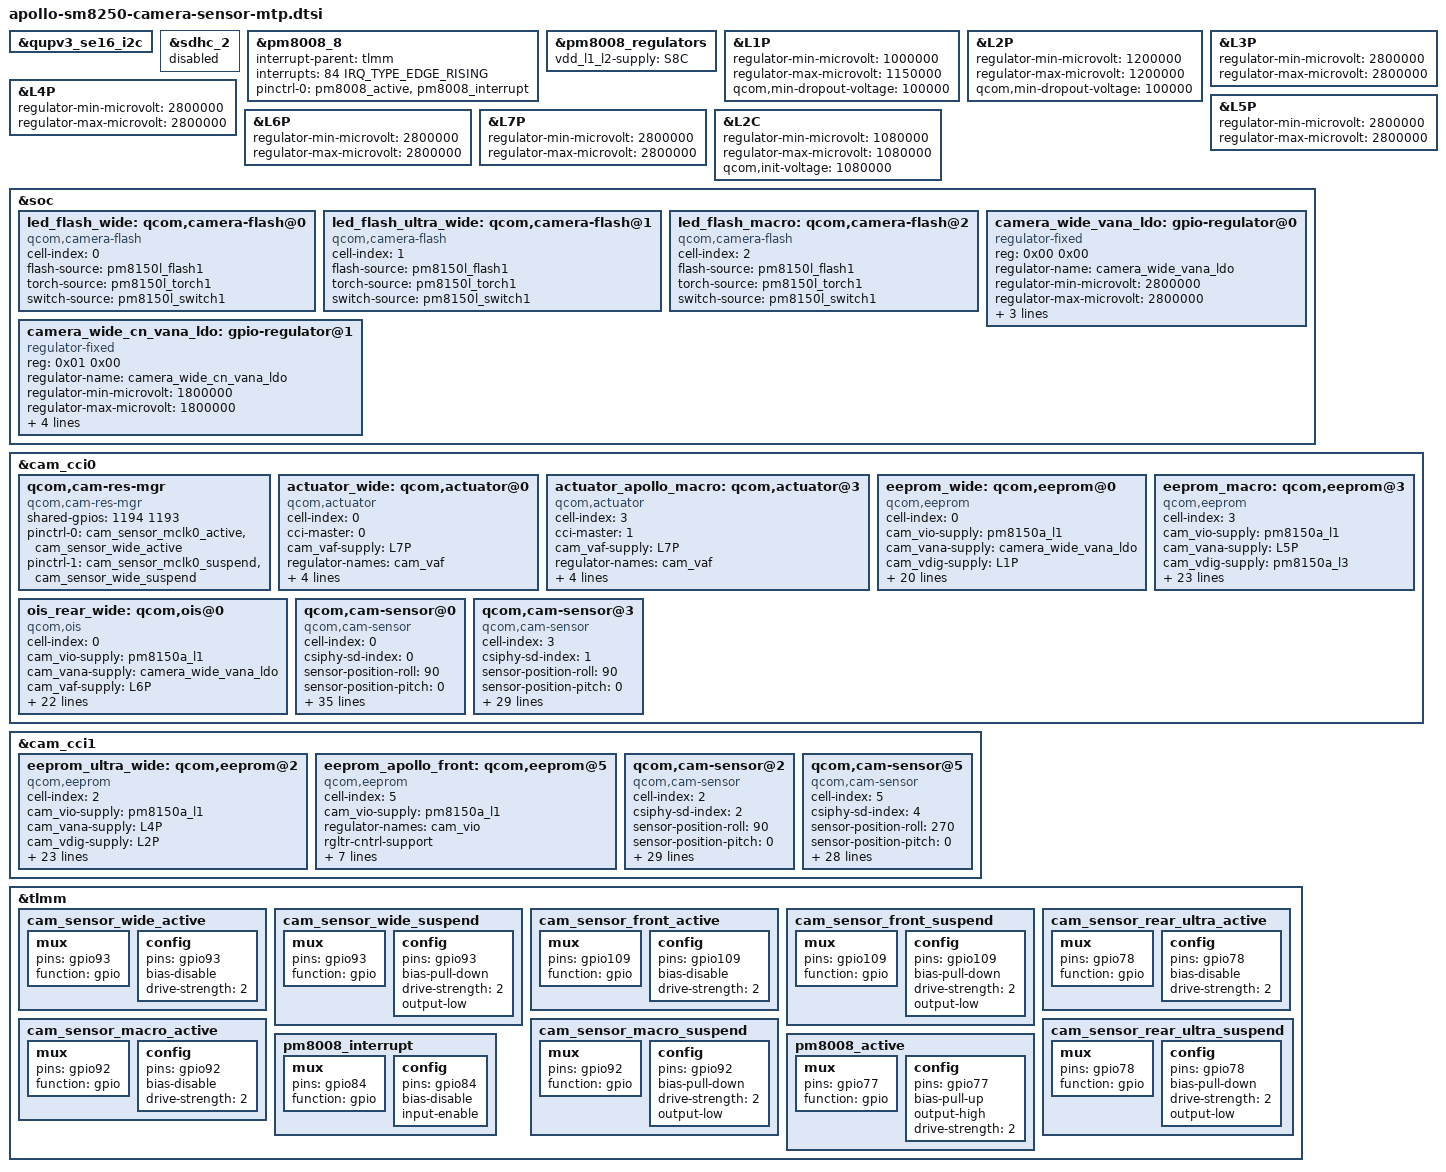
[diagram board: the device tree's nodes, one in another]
&qupv3_se16_i2c {
	status = "ok";
	#include "pm8008.dtsi"
};

&sdhc_2 {
	status = "disabled";
};
&pm8008_8 {
	/* PM8008 IRQ STAT */
	interrupt-parent = <&tlmm>;
	interrupts = <84 IRQ_TYPE_EDGE_RISING>;

	pinctrl-names = "default";
	pinctrl-0 = <&pm8008_active &pm8008_interrupt>;
};
&pm8008_regulators {
	vdd_l1_l2-supply = <&S8C>;
};
&L1P {
	regulator-min-microvolt = <1000000>;
	regulator-max-microvolt = <1150000>;
	qcom,min-dropout-voltage = <100000>;
};

&L2P {
	regulator-min-microvolt = <1200000>;
	regulator-max-microvolt = <1200000>;
	qcom,min-dropout-voltage = <100000>;
};

&L3P {
	regulator-min-microvolt = <2800000>;
	regulator-max-microvolt = <2800000>;
};

&L4P {
	regulator-min-microvolt = <2800000>;
	regulator-max-microvolt = <2800000>;
};

&L5P {
	regulator-min-microvolt = <2800000>;
	regulator-max-microvolt = <2800000>;
};

&L6P {
	regulator-min-microvolt = <2800000>;
	regulator-max-microvolt = <2800000>;
};

&L7P {
	regulator-min-microvolt = <2800000>;
	regulator-max-microvolt = <2800000>;
};
&L2C {
     regulator-min-microvolt = <1080000>;
     regulator-max-microvolt = <1080000>;
     qcom,init-voltage = <1080000>;
};

&soc {
	led_flash_wide: qcom,camera-flash@0 {
		cell-index = <0>;
		compatible = "qcom,camera-flash";
		flash-source = <&pm8150l_flash1>;
		torch-source = <&pm8150l_torch1>;
		switch-source = <&pm8150l_switch1>;
		status = "ok";
	};
	led_flash_ultra_wide: qcom,camera-flash@1 {
		cell-index = <1>;
		compatible = "qcom,camera-flash";
		flash-source = <&pm8150l_flash1>;
		torch-source = <&pm8150l_torch1>;
		switch-source = <&pm8150l_switch1>;
		status = "ok";
	};

	led_flash_macro: qcom,camera-flash@2 {
		cell-index = <2>;
		compatible = "qcom,camera-flash";
		flash-source = <&pm8150l_flash1>;
		torch-source = <&pm8150l_torch1>;
		switch-source = <&pm8150l_switch1>;
		status = "ok";
	};

	camera_wide_vana_ldo: gpio-regulator@0 {
		compatible = "regulator-fixed";
		reg = <0x00 0x00>;
		regulator-name = "camera_wide_vana_ldo";
		regulator-min-microvolt = <2800000>;
		regulator-max-microvolt = <2800000>;
		regulator-enable-ramp-delay = <135>;
		enable-active-high;
		gpio = <&pm8150l_gpios 1 0>;
		//vin-supply = <&pm8150a_bob>;
	};

	camera_wide_cn_vana_ldo: gpio-regulator@1 {
		compatible = "regulator-fixed";
		reg = <0x01 0x00>;
		regulator-name = "camera_wide_cn_vana_ldo";
		regulator-min-microvolt = <1800000>;
		regulator-max-microvolt = <1800000>;
		regulator-enable-ramp-delay = <135>;
		enable-active-high;
		gpio = <&pm8150l_gpios 1 0>;
		vin-supply = <&S5A>;
	};
};

&cam_cci0 {
	qcom,cam-res-mgr {
		compatible = "qcom,cam-res-mgr";
		status = "ok";
		shared-gpios = <1194 1193>;
		pinctrl-names = "cam_res_mgr_default", "cam_res_mgr_suspend";
		pinctrl-0 = <&cam_sensor_mclk0_active
					&cam_sensor_wide_active>;
		pinctrl-1 = <&cam_sensor_mclk0_suspend
					&cam_sensor_wide_suspend>;
	};
	/*  J3S Wide actuator */
	actuator_wide: qcom,actuator@0 {
		cell-index = <0>;
		compatible = "qcom,actuator";
		cci-master = <0>;
		cam_vaf-supply = <&L7P>;
		regulator-names = "cam_vaf";
		rgltr-cntrl-support;
		rgltr-min-voltage = <2800000>;
		rgltr-max-voltage = <2800000>;
		rgltr-load-current = <100000>;
	};
	/*  J3S macro actuator */
	actuator_apollo_macro: qcom,actuator@3 {
		cell-index = <3>;
		compatible = "qcom,actuator";
		cci-master = <1>;
		cam_vaf-supply = <&L7P>;
		regulator-names = "cam_vaf";
		rgltr-cntrl-support;
		rgltr-min-voltage = <2800000>;
		rgltr-max-voltage = <2800000>;
		rgltr-load-current = <100000>;
	};
	/*  J3S Wide eeprom */
	eeprom_wide: qcom,eeprom@0 {
		cell-index = <0>;
		compatible = "qcom,eeprom";
		cam_vio-supply = <&pm8150a_l1>;
		cam_vana-supply = <&camera_wide_vana_ldo>;
		cam_vdig-supply = <&L1P>;
		cam_clk-supply = <&titan_top_gdsc>;
		regulator-names = "cam_vio", "cam_vana", "cam_vdig",
			"cam_clk";
		rgltr-cntrl-support;
		pwm-switch;
		rgltr-min-voltage = <1800000 2800000 1070000 0>;
		rgltr-max-voltage = <1800000 2800000 1070000 0>;
		rgltr-load-current = <120000 80000 1200000 0>;
		gpio-no-mux = <0>;
		gpios = <&tlmm 94 0>,
				<&tlmm 93 0>;
		gpio-reset = <1>;
		gpio-req-tbl-num = <0 1>;
		gpio-req-tbl-flags = <1 0>;
		gpio-req-tbl-label = "CAMIF_MCLK0",
					"CAM_RESET0";
		sensor-mode = <0>;
		cci-master = <0>;
		status = "ok";
		use-shared-clk;
		clocks = <&clock_camcc CAM_CC_MCLK0_CLK>;
		clock-names = "cam_clk";
		clock-cntl-level = "turbo";
		clock-rates = <19200000>;
	};
	/*  J3S Macro eeprom */
	eeprom_macro: qcom,eeprom@3 {
		cell-index = <3>;
		compatible = "qcom,eeprom";
		cam_vio-supply = <&pm8150a_l1>;
		cam_vana-supply = <&L5P>;
		cam_vdig-supply = <&pm8150a_l3>;
		cam_clk-supply = <&titan_top_gdsc>;
		regulator-names = "cam_vio", "cam_vana", "cam_vdig", "cam_clk";
		rgltr-cntrl-support;
		pwm-switch;
		rgltr-min-voltage = <1800000 2800000 1200000 0>;
		rgltr-max-voltage = <1800000 2800000 1200000 0>;
		rgltr-load-current = <180000 2000000 120000 0>;
		gpio-no-mux = <0>;
		pinctrl-names = "cam_default", "cam_suspend";
		pinctrl-0 = <&cam_sensor_mclk1_active
				&cam_sensor_macro_active>;
		pinctrl-1 = <&cam_sensor_mclk1_suspend
				&cam_sensor_macro_suspend>;
		gpios = <&tlmm 95 0>,
			<&tlmm 92 0>;
		gpio-reset = <1>;
		gpio-req-tbl-num = <0 1>;
		gpio-req-tbl-flags = <1 0>;
		gpio-req-tbl-label = "CAMIF_MCLK1",
					"CAM_RESET1";
		sensor-mode = <0>;
		cci-master = <1>;
		status = "ok";
		clocks = <&clock_camcc CAM_CC_MCLK1_CLK>;
		clock-names = "cam_clk";
		clock-cntl-level = "turbo";
		clock-rates = <19200000>;
	};

	/*  J3S Wide ois */
	ois_rear_wide: qcom,ois@0 {
		cell-index = <0>;
		compatible = "qcom,ois";
		cam_vio-supply = <&pm8150a_l1>;
		cam_vana-supply = <&camera_wide_vana_ldo>;//AVDD1
		cam_vaf-supply = <&L6P>;
		cam_vdig-supply = <&L1P>;
		cam_clk-supply = <&titan_top_gdsc>;
		regulator-names = "cam_vio", "cam_vana", "cam_vdig", "cam_vaf", "cam_clk";
		rgltr-cntrl-support;
		rgltr-min-voltage = <1800000 2800000 1070000 2800000 0>;
		rgltr-max-voltage = <1800000 2800000 1070000 2800000 0>;
		rgltr-load-current = <120000 80000 1200000 100000 0>;
		gpio-no-mux = <0>;
		gpios = <&tlmm 94 0>,
		        <&tlmm 93 0>;
		gpio-reset = <1>;
		gpio-req-tbl-num = <0 1>;
		gpio-req-tbl-flags = <1 0>;
		gpio-req-tbl-label = "CAMIF_MCLK0",
		                     "CAM_RESET0";
		cci-master = <0>;
		status = "ok";
		use-shared-clk;
		clocks = <&clock_camcc CAM_CC_MCLK0_CLK>;
		clock-names = "cam_clk";
		clock-cntl-level = "turbo";
		clock-rates = <19200000>;
	};

	/*  J3S Wide sensor   */
	qcom,cam-sensor@0 {
		cell-index = <0>;
		compatible = "qcom,cam-sensor";
		csiphy-sd-index = <0>;
		sensor-position-roll = <90>;
		sensor-position-pitch = <0>;
		sensor-position-yaw = <180>;
		actuator-src = <&actuator_wide>;
		led-flash-src = <&led_flash_wide>;
		eeprom-src = <&eeprom_wide>;
		ois-src = <&ois_rear_wide>;
		cam_vio-supply = <&pm8150a_l1>;
		cam_vana-supply = <&camera_wide_vana_ldo>;//AVDD1
		cam_v_custom1-supply =<&camera_wide_cn_vana_ldo>;//AVDD2
		cam_vdig-supply = <&L1P>;
		cam_v_custom2-supply = <&L1P>;
		cam_vaf-supply = <&L6P>;
		cam_clk-supply = <&titan_top_gdsc>;
		regulator-names = "cam_vio", "cam_vana", "cam_v_custom1", "cam_vdig",
			"cam_v_custom2","cam_vaf", "cam_clk";
		rgltr-cntrl-support;
		pwm-switch;
		rgltr-min-voltage = <1800000 2800000 1800000 1070000 1100000 2800000 0>;
		rgltr-max-voltage = <1800000 2800000 1800000 1070000 1100000 2800000 0>;
		rgltr-load-current = <120000 80000 80000 1200000 1200000 100000 0>;
		gpio-no-mux = <0>;
		gpios = <&tlmm 94 0>,
				<&tlmm 93 0>;
		gpio-reset = <1>;
		gpio-req-tbl-num = <0 1>;
		gpio-req-tbl-flags = <1 0>;
		gpio-req-tbl-label = "CAMIF_MCLK0",
							"CAM_RESET0";
		sensor-mode = <0>;
		cci-master = <0>;
		status = "ok";
		use-shared-clk;
		clocks = <&clock_camcc CAM_CC_MCLK0_CLK>;
		clock-names = "cam_clk";
		clock-cntl-level = "turbo";
		clock-rates = <19200000>;
	};
	/*  J3S Macro sensor  */
	qcom,cam-sensor@3 {
		cell-index = <3>;
		compatible = "qcom,cam-sensor";
		csiphy-sd-index = <1>;
		sensor-position-roll = <90>;
		sensor-position-pitch = <0>;
		sensor-position-yaw = <180>;
		eeprom-src = <&eeprom_macro>;
		actuator-src = <&actuator_apollo_macro>;
		led-flash-src = <&led_flash_macro>;
		cam_vio-supply = <&pm8150a_l1>;
		cam_vana-supply = <&L5P>;
		cam_vdig-supply = <&pm8150a_l3>;
		cam_clk-supply = <&titan_top_gdsc>;
		regulator-names = "cam_vio","cam_vana", "cam_vdig",
			"cam_clk";
		rgltr-cntrl-support;
		rgltr-min-voltage = <1800000 2800000 1200000 0>;
		rgltr-max-voltage = <1800000 2800000 1200000 0>;
		rgltr-load-current = <180000 120000 120000 0>;
		gpio-no-mux = <0>;
		pinctrl-names = "cam_default", "cam_suspend";
		pinctrl-0 = <&cam_sensor_mclk1_active
				&cam_sensor_macro_active>;
		pinctrl-1 = <&cam_sensor_mclk1_suspend
				&cam_sensor_macro_suspend>;
		gpios = <&tlmm 95 0>,
			<&tlmm 92 0>;
		gpio-reset = <1>;
		gpio-req-tbl-num = <0 1>;
		gpio-req-tbl-flags = <1 0>;
		gpio-req-tbl-label = "CAMIF_MCLK1",
					"CAM_RESET1";
		sensor-mode = <0>;
		cci-master = <1>;
		status = "ok";
		clocks = <&clock_camcc CAM_CC_MCLK1_CLK>;
		clock-names = "cam_clk";
		clock-cntl-level = "turbo";
		clock-rates = <19200000>;
	};
};

&cam_cci1 {
	/*  J3S ULTRA_WIDE eeprom */
	eeprom_ultra_wide: qcom,eeprom@2 {
		cell-index = <2>;
		compatible = "qcom,eeprom";
		cam_vio-supply = <&pm8150a_l1>;
		cam_vana-supply = <&L4P>;
		cam_vdig-supply = <&L2P>;
		cam_clk-supply = <&titan_top_gdsc>;
		regulator-names = "cam_vio", "cam_vana", "cam_vdig", "cam_clk";
		rgltr-cntrl-support;
		pwm-switch;
		rgltr-min-voltage = <1800000 2800000 1200000 0>;
		rgltr-max-voltage = <1800000 2800000 1200000 0>;
		rgltr-load-current = <120000 80000 1056000 0>;
		gpio-no-mux = <0>;
		pinctrl-names = "cam_default", "cam_suspend";
		pinctrl-0 = <&cam_sensor_mclk2_active
				&cam_sensor_rear_ultra_active>;
		pinctrl-1 = <&cam_sensor_mclk2_suspend
				&cam_sensor_rear_ultra_suspend>;
		gpios = <&tlmm 96 0>,
			<&tlmm 78 0>;
		gpio-reset = <1>;
		gpio-req-tbl-num = <0 1>;
		gpio-req-tbl-flags = <1 0>;
		gpio-req-tbl-label = "CAMIF_MCLK2",
					"CAM_RESET2";
		sensor-mode = <0>;
		cci-master = <0>;
		status = "ok";
		clocks = <&clock_camcc CAM_CC_MCLK2_CLK>;
		clock-names = "cam_clk";
		clock-cntl-level = "turbo";
		clock-rates = <19200000>;
	};
	/*  J3S front eeprom */
	eeprom_apollo_front: qcom,eeprom@5 {
		cell-index = <5>;
		compatible = "qcom,eeprom";
		cam_vio-supply = <&pm8150a_l1>;
		regulator-names = "cam_vio";
		rgltr-cntrl-support;
		pwm-switch;
		rgltr-min-voltage = <1800000>;
		rgltr-max-voltage = <1800000>;
		rgltr-load-current = <120000>;
		gpio-no-mux = <0>;
		sensor-mode = <0>;
		cci-master = <1>;
		status = "ok";
	};
	/*  J3S Ultra Wide sensor */
	qcom,cam-sensor@2 {
		cell-index = <2>;
		compatible = "qcom,cam-sensor";
		csiphy-sd-index = <2>;
		sensor-position-roll = <90>;
		sensor-position-pitch = <0>;
		sensor-position-yaw = <180>;
		eeprom-src = <&eeprom_ultra_wide>;
		led-flash-src = <&led_flash_ultra_wide>;
		cam_vio-supply = <&pm8150a_l1>;
		cam_vana-supply = <&L4P>;
		cam_vdig-supply = <&L2P>;
		cam_clk-supply = <&titan_top_gdsc>;
		regulator-names = "cam_vio", "cam_vdig", "cam_vana", "cam_clk";
		rgltr-cntrl-support;
		pwm-switch;
		rgltr-min-voltage = <1800000 1200000 2800000 0>;
		rgltr-max-voltage = <1800000 1200000 2800000 0>;
		rgltr-load-current = <120000 1056000 80000 0>;
		gpio-no-mux = <0>;
		pinctrl-names = "cam_default", "cam_suspend";
		pinctrl-0 = <&cam_sensor_mclk2_active
			     &cam_sensor_rear_ultra_active>;
		pinctrl-1 = <&cam_sensor_mclk2_suspend
			     &cam_sensor_rear_ultra_suspend>;
		gpios = <&tlmm 96 0>,
				<&tlmm 78 0>;
		gpio-reset = <1>;
		gpio-req-tbl-num = <0 1>;
		gpio-req-tbl-flags = <1 0>;
		gpio-req-tbl-label = "CAMIF_MCLK2",
					"CAM_RESET2";
		sensor-mode = <0>;
		cci-master = <0>;
		status = "ok";
		clocks = <&clock_camcc CAM_CC_MCLK2_CLK>;
		clock-names = "cam_clk";
		clock-cntl-level = "turbo";
		clock-rates = <19200000>;
	};
	/*  J3S Front  */
	qcom,cam-sensor@5 {
		cell-index = <5>;
		compatible = "qcom,cam-sensor";
		csiphy-sd-index = <4>;
		sensor-position-roll = <270>;
		sensor-position-pitch = <0>;
		sensor-position-yaw = <0>;
		eeprom-src = <&eeprom_apollo_front>;
		cam_vio-supply = <&pm8150a_l1>;
		cam_vana-supply = <&L3P>;
		cam_vdig-supply = <&L2C>;
		cam_clk-supply = <&titan_top_gdsc>;
		regulator-names = "cam_vio", "cam_vana", "cam_vdig", "cam_clk";
		rgltr-cntrl-support;
		pwm-switch;
		rgltr-min-voltage = <1800000 2800000 1080000 0>;
		rgltr-max-voltage = <1800000 2800000 1080000 0>;
		rgltr-load-current = <120000 80000 120000 0>;
		gpio-no-mux = <0>;
		pinctrl-names = "cam_default", "cam_suspend";
		pinctrl-0 = <&cam_sensor_mclk4_active
				     &cam_sensor_front_active>;
		pinctrl-1 = <&cam_sensor_mclk4_suspend
				     &cam_sensor_front_suspend>;
		gpios = <&tlmm 98 0>,
			    <&tlmm 109 0>;
		gpio-reset = <1>;
		gpio-req-tbl-num = <0 1>;
		gpio-req-tbl-flags = <1 0>;
		gpio-req-tbl-label = "CAMIF_MCLK4",
					"CAM_RESET4";
		sensor-mode = <0>;
		cci-master = <1>;
		status = "ok";
		clocks = <&clock_camcc CAM_CC_MCLK4_CLK>;
		clock-names = "cam_clk";
		clock-cntl-level = "turbo";
		clock-rates = <19200000>;
	};
};

&tlmm {
	cam_sensor_wide_active: cam_sensor_wide_active {
		/* RESET WIDE */
		mux {
			pins = "gpio93";
			function = "gpio";
		};

		config {
			pins = "gpio93";
			bias-disable; /* No PULL */
			drive-strength = <2>; /* 2 MA */
		};
	};
	cam_sensor_wide_suspend: cam_sensor_wide_suspend {
		mux {
			pins = "gpio93";
			function = "gpio";
		};

		config {
			pins = "gpio93";
			bias-pull-down; /* PULL DOWN */
			drive-strength = <2>; /* 2 MA */
			output-low;
		};
	};
	cam_sensor_front_active: cam_sensor_front_active {
		/* RESET FRONT */
		mux {
			pins = "gpio109";
			function = "gpio";
		};

		config {
			pins = "gpio109";
			bias-disable; /* No PULL */
			drive-strength = <2>; /* 2 MA */
		};
	};
	cam_sensor_front_suspend: cam_sensor_front_suspend {
		mux {
			pins = "gpio109";
			function = "gpio";
		};

		config {
			pins = "gpio109";
			bias-pull-down; /* PULL DOWN */
			drive-strength = <2>; /* 2 MA */
			output-low;
		};
	};
	cam_sensor_rear_ultra_active: cam_sensor_rear_ultra_active {
		/* RESET REAR ULTRA */
		mux {
			pins = "gpio78";
			function = "gpio";
		};

		config {
			pins = "gpio78";
			bias-disable; /* No PULL */
			drive-strength = <2>; /* 2 MA */
		};
	};
	cam_sensor_rear_ultra_suspend: cam_sensor_rear_ultra_suspend {
		mux {
			pins = "gpio78";
			function = "gpio";
		};

		config {
			pins = "gpio78";
			bias-pull-down; /* PULL DOWN */
			drive-strength = <2>; /* 2 MA */
			output-low;
		};
	};
	cam_sensor_macro_active: cam_sensor_macro_active {
		/* RESET MACRO */
		mux {
			pins = "gpio92";
			function = "gpio";
		};

		config {
			pins = "gpio92";
			bias-disable; /* No PULL */
			drive-strength = <2>; /* 2 MA */
		};
	};
	cam_sensor_macro_suspend: cam_sensor_macro_suspend {
		mux {
			pins = "gpio92";
			function = "gpio";
		};

		config {
			pins = "gpio92";
			bias-pull-down; /* PULL DOWN */
			drive-strength = <2>; /* 2 MA */
			output-low;
		};
	};
};

&tlmm{
	pm8008_interrupt: pm8008_interrupt {
		mux {
			pins = "gpio84";
			function = "gpio";
		};

		config {
			pins = "gpio84";
			bias-disable;
			input-enable;
		};
	};

	pm8008_active: pm8008_active {
		mux {
			pins = "gpio77";
			function = "gpio";
		};

		config {
			pins = "gpio77";
			bias-pull-up;
			output-high;
			drive-strength = <2>;
		};
	};
};
